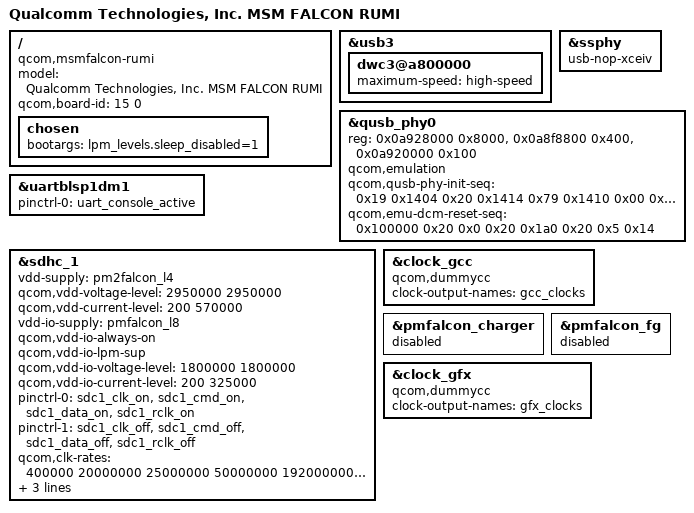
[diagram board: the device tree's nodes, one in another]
/* Copyright (c) 2016, The Linux Foundation. All rights reserved.
 *
 * This program is free software; you can redistribute it and/or modify
 * it under the terms of the GNU General Public License version 2 and
 * only version 2 as published by the Free Software Foundation.
 *
 * This program is distributed in the hope that it will be useful,
 * but WITHOUT ANY WARRANTY; without even the implied warranty of
 * MERCHANTABILITY or FITNESS FOR A PARTICULAR PURPOSE.  See the
 * GNU General Public License for more details.
 */


/dts-v1/;

#include "msmfalcon.dtsi"
#include "msmfalcon-pinctrl.dtsi"

/ {
	model = "Qualcomm Technologies, Inc. MSM FALCON RUMI";
	compatible = "qcom,msmfalcon-rumi", "qcom,msmfalcon", "qcom,rumi";
	qcom,board-id = <15 0>;

	chosen {
		bootargs = "lpm_levels.sleep_disabled=1";
	};
};

&usb3 {
	/delete-property/ USB3_GDSC-supply;
	dwc3@a800000 {
		maximum-speed = "high-speed";
	};
};

&ssphy {
	compatible =  "usb-nop-xceiv";
};

&qusb_phy0 {
	reg = <0x0a928000 0x8000>,
		<0x0a8f8800 0x400>,
		<0x0a920000 0x100>;
		reg-names = "qusb_phy_base",
			"qscratch_base",
			"emu_phy_base";
		qcom,emulation;
		qcom,qusb-phy-init-seq = <0x19 0x1404
					0x20 0x1414
					0x79 0x1410
					0x00 0x1418
					0x99 0x1404
					0x04 0x1408
					0xd9 0x1404>;
		qcom,emu-dcm-reset-seq = <0x100000 0x20
					0x0 0x20
					0x1a0 0x20
					0x5 0x14>;
};

&uartblsp1dm1 {
	status = "ok";
	pinctrl-names = "default";
	pinctrl-0 = <&uart_console_active>;
};

&sdhc_1 {
	/* device core power supply */
	vdd-supply = <&pm2falcon_l4>;
	qcom,vdd-voltage-level = <2950000 2950000>;
	qcom,vdd-current-level = <200 570000>;

	/* device communication power supply */
	vdd-io-supply = <&pmfalcon_l8>;
	qcom,vdd-io-always-on;
	qcom,vdd-io-lpm-sup;
	qcom,vdd-io-voltage-level = <1800000 1800000>;
	qcom,vdd-io-current-level = <200 325000>;

	pinctrl-names = "active", "sleep";
	pinctrl-0 = <&sdc1_clk_on &sdc1_cmd_on &sdc1_data_on &sdc1_rclk_on>;
	pinctrl-1 = <&sdc1_clk_off &sdc1_cmd_off &sdc1_data_off &sdc1_rclk_off>;

	qcom,clk-rates = <400000 20000000 25000000 50000000 192000000
								384000000>;

	qcom,nonremovable;
	qcom,bus-speed-mode = "HS400_1p8v", "HS200_1p8v", "DDR_1p8v";

	status = "ok";
};

&clock_gcc {
	compatible = "qcom,dummycc";
	clock-output-names = "gcc_clocks";
};

&pmfalcon_charger {
	status = "disabled";
};

&pmfalcon_fg {
	status = "disabled";
};

&clock_gfx {
	compatible = "qcom,dummycc";
	clock-output-names = "gfx_clocks";
};
